# CBASS0_ISC register map
Vendor: Texas Instruments
Registers are 32-bit, read-write, reset 0x0 unless marked. A register's access mark holds for its fields unless they carry their own. Offsets are as the file gives them; [hi:lo] are bit positions; {n}, {i} and the like mark numbered series; 'fields as' and 'values as' point back to an identical list.

## CBASS0_ISC (part 2 of 2)
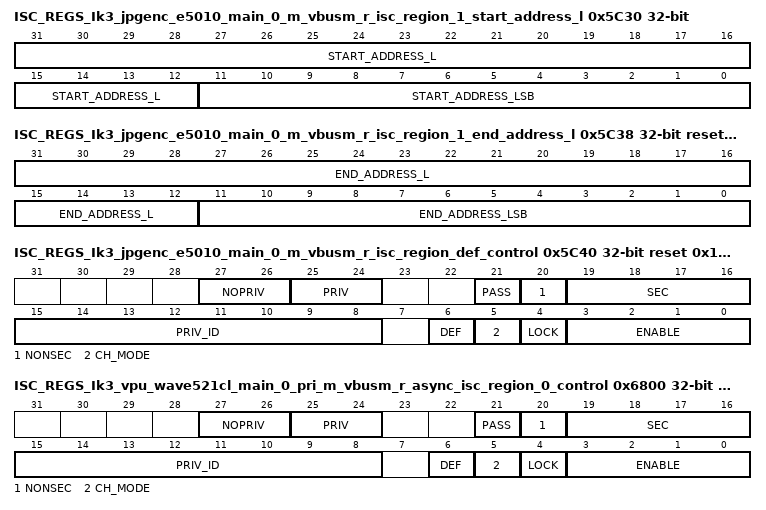
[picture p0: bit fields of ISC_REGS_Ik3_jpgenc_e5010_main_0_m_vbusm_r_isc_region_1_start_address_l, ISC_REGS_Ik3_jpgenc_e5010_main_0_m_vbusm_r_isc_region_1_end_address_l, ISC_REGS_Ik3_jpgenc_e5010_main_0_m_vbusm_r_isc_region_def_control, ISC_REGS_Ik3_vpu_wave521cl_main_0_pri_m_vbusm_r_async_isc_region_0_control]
0x5C30 ISC_REGS_Ik3_jpgenc_e5010_main_0_m_vbusm_r_isc_region_1_start_address_l — The ISC Region 1 Start Address Low Register defines the start address bits 31 to 0 for the initiator Ik3_jpgenc_e5010_main_0.m_vbusm_r region 1 ISC.
  [31:12] START_ADDRESS_L — Start address bits 31 to 12.
  [11:0] START_ADDRESS_LSB — Start address bits 11 to 0 must be 0 as address must be 4KB aligned in address mode. Can also be channel number in channel mode.
0x5C34 ISC_REGS_Ik3_jpgenc_e5010_main_0_m_vbusm_r_isc_region_1_start_address_h — The ISC Region 1 Start Address High Register defines the start address bits 47 to 32 for the initiator Ik3_jpgenc_e5010_main_0.m_vbusm_r region 1 ISC.
  [15:0] START_ADDRESS_H — Start address bits 47 to 32.
0x5C38 ISC_REGS_Ik3_jpgenc_e5010_main_0_m_vbusm_r_isc_region_1_end_address_l access per field reset 0xFFF — The ISC Region 1 End Address Low Register defines the end included address bits 31 to 0 for the initiator Ik3_jpgenc_e5010_main_0.m_vbusm_r region 1 ISC.
  [31:12] END_ADDRESS_L rw — End address bits 31 to 12 to include in the match.
  [11:0] END_ADDRESS_LSB ro — End address bits 11 to 0 are forced to Fs as address must be 4KB aligned.
0x5C3C ISC_REGS_Ik3_jpgenc_e5010_main_0_m_vbusm_r_isc_region_1_end_address_h — The ISC Region 1 End Address High Register defines the end address bits 47 to 32 for the initiator Ik3_jpgenc_e5010_main_0.m_vbusm_r region 1 ISC.
  [15:0] END_ADDRESS_H — End address bits 47 to 32.
0x5C40 ISC_REGS_Ik3_jpgenc_e5010_main_0_m_vbusm_r_isc_region_def_control access not given reset 0x10BE4A — The ISC Default Region Control Register defines the control fields for the initiator Ik3_jpgenc_e5010_main_0.m_vbusm_r region 2 ISC.
  [27:26] NOPRIV rw — Clear output priv attribute. If each bit is set then the outgoing priv bit is cleared, else the bit is unchanged. Do not set both priv and nopriv for the same bit.
  [25:24] PRIV rw — Set outgoing priv attribute. If each bit is set then the outgoing priv bit is set, else the bit is unchanged. Do not set both priv and nopriv for the same bit.
  [21] PASS rw — No privID replacement. A value of 1 will pass through privid value. A value of 0 will replace privid with priv_id field value.
  [20] NONSEC rw — Make outgoing non-secure. A value of 1 forces secure clear, others do nothing. Do not set both sec and nonsec.
  [19:16] SEC rw — Make outgoing secure. A value of 0xA forces secure set, others do nothing. Do not set both sec and nonsec.
  [15:8] PRIV_ID rw — Priv ID value to use if pass is 0.
  [6] DEF ro — Default region indication. The default region is used when all other regions do not match.
  [5] CH_MODE ro — Enable channel mode to match region to a chanid value. Otherwise use address mode to match region to an address range.
  [4] LOCK — Lock region. Once set, the region values cannot be modified. (access R/W1TS)
  [3:0] ENABLE ro — Enable region. A value of 0xA enables, others disable.
{0x6800+0x20*i} ISC_REGS_Ik3_vpu_wave521cl_main_0_pri_m_vbusm_r_async_isc_region_{i}_control access not given reset 0x10BF00 (i=0..4) — The ISC Region {i} Control Register defines the control fields for the initiator Ik3_vpu_wave521cl_main_0.pri_m_vbusm_r_async region {i} ISC.
  [27:26] NOPRIV rw — Clear output priv attribute. If each bit is set then the outgoing priv bit is cleared.
  [25:24] PRIV rw — Set outgoing priv attribute. If each bit is set then the outgoing priv bit is set.
  [21] PASS rw — No privID replacement, pass through value.
  [20] NONSEC rw — Make outgoing non-secure.
  [19:16] SEC rw — Make outgoing secure. A value of 0xA enables, others disable.
  [15:8] PRIV_ID rw
  [6] DEF ro — Default region indication. The default region is used when all other regions do not match.
  [5] CH_MODE rw — Enable channel mode to match region to a chanid value. Otherwise use address mode to match region to an address range.
  [4] LOCK — Lock region. Once set the region values cannot be modified. (access R/W1TS)
  [3:0] ENABLE rw — Enable region. A value of 0xA enables, others disable.
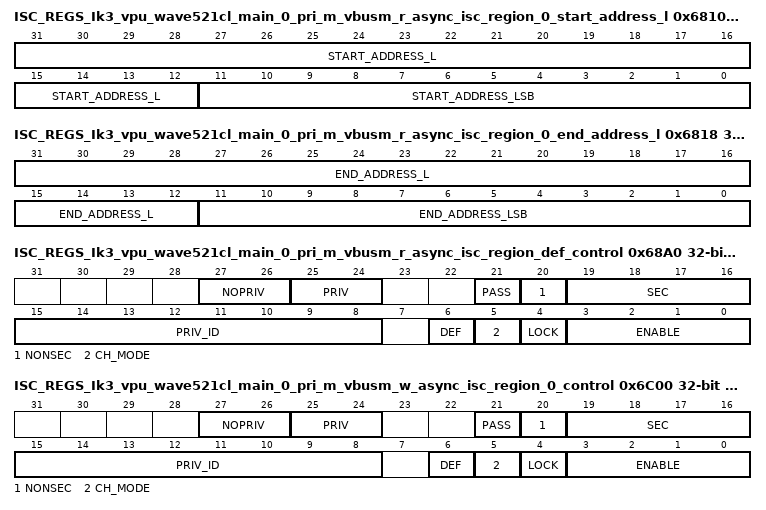
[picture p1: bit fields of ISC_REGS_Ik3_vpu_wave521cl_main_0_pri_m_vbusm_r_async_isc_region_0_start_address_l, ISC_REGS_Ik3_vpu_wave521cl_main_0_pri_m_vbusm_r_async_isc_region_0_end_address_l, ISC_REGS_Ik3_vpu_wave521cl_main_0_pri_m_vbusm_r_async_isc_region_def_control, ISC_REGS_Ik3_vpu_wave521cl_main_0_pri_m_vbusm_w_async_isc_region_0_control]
{0x6810+0x20*i} ISC_REGS_Ik3_vpu_wave521cl_main_0_pri_m_vbusm_r_async_isc_region_{i}_start_address_l (i=0..4) — The ISC Region {i} Start Address Low Register defines the start address bits 31 to 0 for the initiator Ik3_vpu_wave521cl_main_0.pri_m_vbusm_r_async region {i} ISC.
  fields as ISC_REGS_Ik3_jpgenc_e5010_main_0_m_vbusm_r_isc_region_1_start_address_l
{0x6814+0x20*i} ISC_REGS_Ik3_vpu_wave521cl_main_0_pri_m_vbusm_r_async_isc_region_{i}_start_address_h (i=0..4) — The ISC Region {i} Start Address High Register defines the start address bits 47 to 32 for the initiator Ik3_vpu_wave521cl_main_0.pri_m_vbusm_r_async region {i} ISC.
  [15:0] START_ADDRESS_H — Start address bits 47 to 32.
{0x6818+0x20*i} ISC_REGS_Ik3_vpu_wave521cl_main_0_pri_m_vbusm_r_async_isc_region_{i}_end_address_l access per field reset 0xFFF (i=0..4) — The ISC Region {i} End Address Low Register defines the end included address bits 31 to 0 for the initiator Ik3_vpu_wave521cl_main_0.pri_m_vbusm_r_async region {i} ISC.
  fields as ISC_REGS_Ik3_jpgenc_e5010_main_0_m_vbusm_r_isc_region_1_end_address_l
{0x681C+0x20*i} ISC_REGS_Ik3_vpu_wave521cl_main_0_pri_m_vbusm_r_async_isc_region_{i}_end_address_h (i=0..4) — The ISC Region {i} End Address High Register defines the end address bits 47 to 32 for the initiator Ik3_vpu_wave521cl_main_0.pri_m_vbusm_r_async region {i} ISC.
  [15:0] END_ADDRESS_H — End address bits 47 to 32.
0x68A0 ISC_REGS_Ik3_vpu_wave521cl_main_0_pri_m_vbusm_r_async_isc_region_def_control access not given reset 0x10BF4A — The ISC Default Region Control Register defines the control fields for the initiator Ik3_vpu_wave521cl_main_0.pri_m_vbusm_r_async region 5 ISC.
  fields as ISC_REGS_Ik3_jpgenc_e5010_main_0_m_vbusm_r_isc_region_def_control
{0x6C00+0x20*i} ISC_REGS_Ik3_vpu_wave521cl_main_0_pri_m_vbusm_w_async_isc_region_{i}_control access not given reset 0x10BF00 (i=0..4) — The ISC Region {i} Control Register defines the control fields for the initiator Ik3_vpu_wave521cl_main_0.pri_m_vbusm_w_async region {i} ISC.
  fields as ISC_REGS_Ik3_vpu_wave521cl_main_0_pri_m_vbusm_r_async_isc_region_0_control
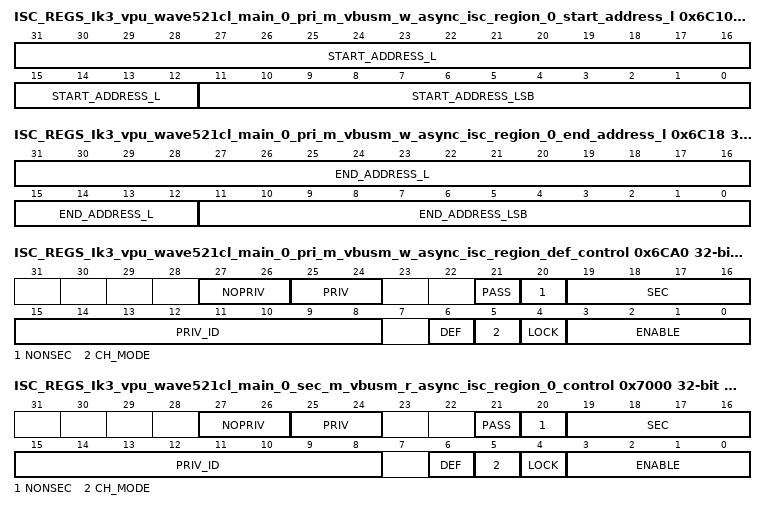
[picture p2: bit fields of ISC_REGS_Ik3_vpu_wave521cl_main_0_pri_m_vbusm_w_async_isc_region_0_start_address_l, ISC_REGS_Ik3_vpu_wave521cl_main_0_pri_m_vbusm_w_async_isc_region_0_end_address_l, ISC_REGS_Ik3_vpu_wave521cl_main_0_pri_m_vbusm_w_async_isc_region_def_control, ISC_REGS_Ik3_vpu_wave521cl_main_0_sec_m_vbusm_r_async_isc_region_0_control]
{0x6C10+0x20*i} ISC_REGS_Ik3_vpu_wave521cl_main_0_pri_m_vbusm_w_async_isc_region_{i}_start_address_l (i=0..4) — The ISC Region {i} Start Address Low Register defines the start address bits 31 to 0 for the initiator Ik3_vpu_wave521cl_main_0.pri_m_vbusm_w_async region {i} ISC.
  fields as ISC_REGS_Ik3_jpgenc_e5010_main_0_m_vbusm_r_isc_region_1_start_address_l
{0x6C14+0x20*i} ISC_REGS_Ik3_vpu_wave521cl_main_0_pri_m_vbusm_w_async_isc_region_{i}_start_address_h (i=0..4) — The ISC Region {i} Start Address High Register defines the start address bits 47 to 32 for the initiator Ik3_vpu_wave521cl_main_0.pri_m_vbusm_w_async region {i} ISC.
  [15:0] START_ADDRESS_H — Start address bits 47 to 32.
{0x6C18+0x20*i} ISC_REGS_Ik3_vpu_wave521cl_main_0_pri_m_vbusm_w_async_isc_region_{i}_end_address_l access per field reset 0xFFF (i=0..4) — The ISC Region {i} End Address Low Register defines the end included address bits 31 to 0 for the initiator Ik3_vpu_wave521cl_main_0.pri_m_vbusm_w_async region {i} ISC.
  fields as ISC_REGS_Ik3_jpgenc_e5010_main_0_m_vbusm_r_isc_region_1_end_address_l
{0x6C1C+0x20*i} ISC_REGS_Ik3_vpu_wave521cl_main_0_pri_m_vbusm_w_async_isc_region_{i}_end_address_h (i=0..4) — The ISC Region {i} End Address High Register defines the end address bits 47 to 32 for the initiator Ik3_vpu_wave521cl_main_0.pri_m_vbusm_w_async region {i} ISC.
  [15:0] END_ADDRESS_H — End address bits 47 to 32.
0x6CA0 ISC_REGS_Ik3_vpu_wave521cl_main_0_pri_m_vbusm_w_async_isc_region_def_control access not given reset 0x10BF4A — The ISC Default Region Control Register defines the control fields for the initiator Ik3_vpu_wave521cl_main_0.pri_m_vbusm_w_async region 5 ISC.
  fields as ISC_REGS_Ik3_jpgenc_e5010_main_0_m_vbusm_r_isc_region_def_control
0x7000 ISC_REGS_Ik3_vpu_wave521cl_main_0_sec_m_vbusm_r_async_isc_region_0_control access not given reset 0x10BF00 — The ISC Region 0 Control Register defines the control fields for the initiator Ik3_vpu_wave521cl_main_0.sec_m_vbusm_r_async region 0 ISC.
  fields as ISC_REGS_Ik3_vpu_wave521cl_main_0_pri_m_vbusm_r_async_isc_region_0_control
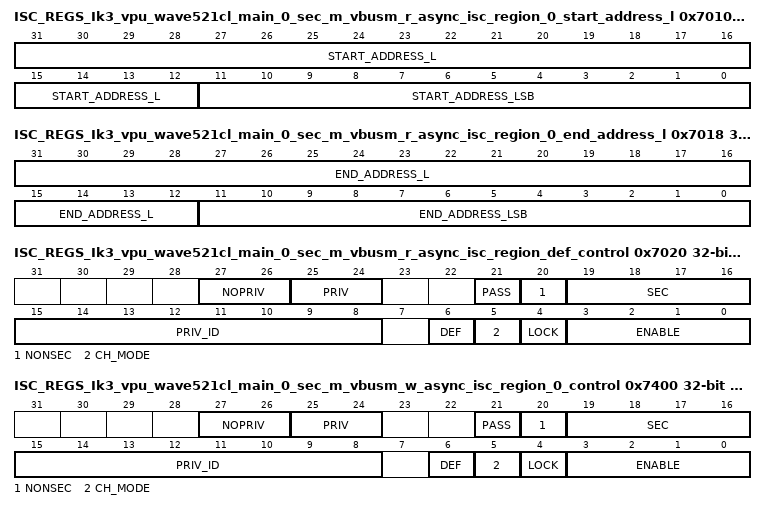
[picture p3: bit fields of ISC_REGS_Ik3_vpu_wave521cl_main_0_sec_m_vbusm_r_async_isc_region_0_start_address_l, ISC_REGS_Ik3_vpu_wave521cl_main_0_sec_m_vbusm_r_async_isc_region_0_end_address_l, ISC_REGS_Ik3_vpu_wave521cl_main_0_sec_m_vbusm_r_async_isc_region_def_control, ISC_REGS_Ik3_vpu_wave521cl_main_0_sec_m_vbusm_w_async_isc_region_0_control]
0x7010 ISC_REGS_Ik3_vpu_wave521cl_main_0_sec_m_vbusm_r_async_isc_region_0_start_address_l — The ISC Region 0 Start Address Low Register defines the start address bits 31 to 0 for the initiator Ik3_vpu_wave521cl_main_0.sec_m_vbusm_r_async region 0 ISC.
  fields as ISC_REGS_Ik3_jpgenc_e5010_main_0_m_vbusm_r_isc_region_1_start_address_l
0x7014 ISC_REGS_Ik3_vpu_wave521cl_main_0_sec_m_vbusm_r_async_isc_region_0_start_address_h — The ISC Region 0 Start Address High Register defines the start address bits 47 to 32 for the initiator Ik3_vpu_wave521cl_main_0.sec_m_vbusm_r_async region 0 ISC.
  [15:0] START_ADDRESS_H — Start address bits 47 to 32.
0x7018 ISC_REGS_Ik3_vpu_wave521cl_main_0_sec_m_vbusm_r_async_isc_region_0_end_address_l access per field reset 0xFFF — The ISC Region 0 End Address Low Register defines the end included address bits 31 to 0 for the initiator Ik3_vpu_wave521cl_main_0.sec_m_vbusm_r_async region 0 ISC.
  fields as ISC_REGS_Ik3_jpgenc_e5010_main_0_m_vbusm_r_isc_region_1_end_address_l
0x701C ISC_REGS_Ik3_vpu_wave521cl_main_0_sec_m_vbusm_r_async_isc_region_0_end_address_h — The ISC Region 0 End Address High Register defines the end address bits 47 to 32 for the initiator Ik3_vpu_wave521cl_main_0.sec_m_vbusm_r_async region 0 ISC.
  [15:0] END_ADDRESS_H — End address bits 47 to 32.
0x7020 ISC_REGS_Ik3_vpu_wave521cl_main_0_sec_m_vbusm_r_async_isc_region_def_control access not given reset 0x10BF4A — The ISC Default Region Control Register defines the control fields for the initiator Ik3_vpu_wave521cl_main_0.sec_m_vbusm_r_async region 1 ISC.
  fields as ISC_REGS_Ik3_jpgenc_e5010_main_0_m_vbusm_r_isc_region_def_control
0x7400 ISC_REGS_Ik3_vpu_wave521cl_main_0_sec_m_vbusm_w_async_isc_region_0_control access not given reset 0x10BF00 — The ISC Region 0 Control Register defines the control fields for the initiator Ik3_vpu_wave521cl_main_0.sec_m_vbusm_w_async region 0 ISC.
  fields as ISC_REGS_Ik3_vpu_wave521cl_main_0_pri_m_vbusm_r_async_isc_region_0_control
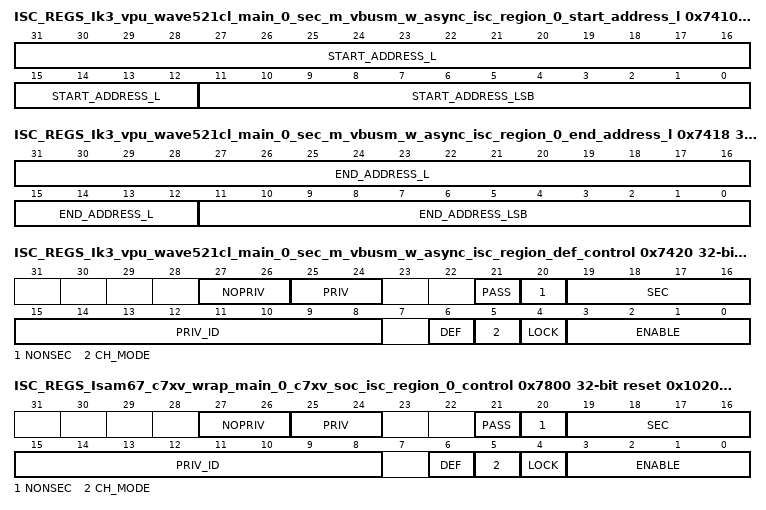
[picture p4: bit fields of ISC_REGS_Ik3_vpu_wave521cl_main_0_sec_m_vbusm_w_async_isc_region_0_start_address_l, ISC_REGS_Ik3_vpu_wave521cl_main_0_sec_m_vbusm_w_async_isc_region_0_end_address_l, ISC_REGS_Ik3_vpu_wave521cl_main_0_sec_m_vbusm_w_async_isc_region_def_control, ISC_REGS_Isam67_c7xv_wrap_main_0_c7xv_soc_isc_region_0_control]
0x7410 ISC_REGS_Ik3_vpu_wave521cl_main_0_sec_m_vbusm_w_async_isc_region_0_start_address_l — The ISC Region 0 Start Address Low Register defines the start address bits 31 to 0 for the initiator Ik3_vpu_wave521cl_main_0.sec_m_vbusm_w_async region 0 ISC.
  fields as ISC_REGS_Ik3_jpgenc_e5010_main_0_m_vbusm_r_isc_region_1_start_address_l
0x7414 ISC_REGS_Ik3_vpu_wave521cl_main_0_sec_m_vbusm_w_async_isc_region_0_start_address_h — The ISC Region 0 Start Address High Register defines the start address bits 47 to 32 for the initiator Ik3_vpu_wave521cl_main_0.sec_m_vbusm_w_async region 0 ISC.
  [15:0] START_ADDRESS_H — Start address bits 47 to 32.
0x7418 ISC_REGS_Ik3_vpu_wave521cl_main_0_sec_m_vbusm_w_async_isc_region_0_end_address_l access per field reset 0xFFF — The ISC Region 0 End Address Low Register defines the end included address bits 31 to 0 for the initiator Ik3_vpu_wave521cl_main_0.sec_m_vbusm_w_async region 0 ISC.
  fields as ISC_REGS_Ik3_jpgenc_e5010_main_0_m_vbusm_r_isc_region_1_end_address_l
0x741C ISC_REGS_Ik3_vpu_wave521cl_main_0_sec_m_vbusm_w_async_isc_region_0_end_address_h — The ISC Region 0 End Address High Register defines the end address bits 47 to 32 for the initiator Ik3_vpu_wave521cl_main_0.sec_m_vbusm_w_async region 0 ISC.
  [15:0] END_ADDRESS_H — End address bits 47 to 32.
0x7420 ISC_REGS_Ik3_vpu_wave521cl_main_0_sec_m_vbusm_w_async_isc_region_def_control access not given reset 0x10BF4A — The ISC Default Region Control Register defines the control fields for the initiator Ik3_vpu_wave521cl_main_0.sec_m_vbusm_w_async region 1 ISC.
  fields as ISC_REGS_Ik3_jpgenc_e5010_main_0_m_vbusm_r_isc_region_def_control
0x7800 ISC_REGS_Isam67_c7xv_wrap_main_0_c7xv_soc_isc_region_0_control access not given reset 0x102000 — The ISC Region 0 Control Register defines the control fields for the initiator Isam67_c7xv_wrap_main_0.c7xv_soc region 0 ISC.
  fields as ISC_REGS_Ik3_vpu_wave521cl_main_0_pri_m_vbusm_r_async_isc_region_0_control
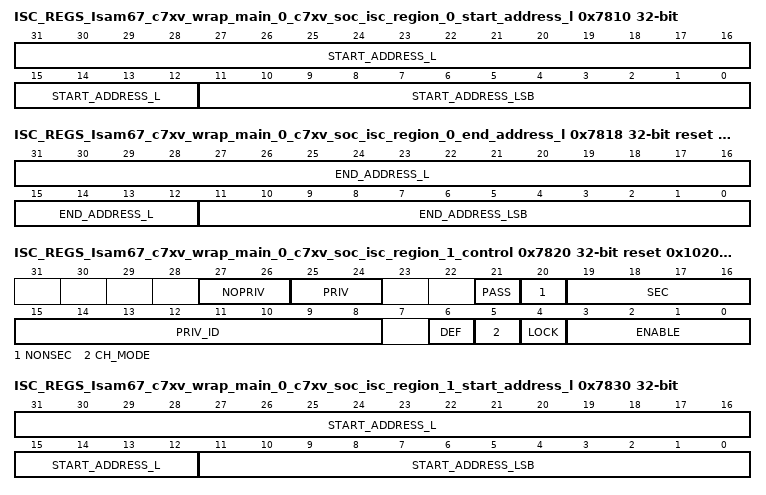
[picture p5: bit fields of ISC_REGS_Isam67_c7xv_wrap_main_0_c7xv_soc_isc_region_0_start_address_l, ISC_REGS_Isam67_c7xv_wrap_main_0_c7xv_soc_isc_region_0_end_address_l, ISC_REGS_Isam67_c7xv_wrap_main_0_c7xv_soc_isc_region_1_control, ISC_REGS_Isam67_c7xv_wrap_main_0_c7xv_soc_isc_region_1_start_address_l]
0x7810 ISC_REGS_Isam67_c7xv_wrap_main_0_c7xv_soc_isc_region_0_start_address_l — The ISC Region 0 Start Address Low Register defines the start address bits 31 to 0 for the initiator Isam67_c7xv_wrap_main_0.c7xv_soc region 0 ISC.
  fields as ISC_REGS_Ik3_jpgenc_e5010_main_0_m_vbusm_r_isc_region_1_start_address_l
0x7814 ISC_REGS_Isam67_c7xv_wrap_main_0_c7xv_soc_isc_region_0_start_address_h — The ISC Region 0 Start Address High Register defines the start address bits 47 to 32 for the initiator Isam67_c7xv_wrap_main_0.c7xv_soc region 0 ISC.
  [15:0] START_ADDRESS_H — Start address bits 47 to 32.
0x7818 ISC_REGS_Isam67_c7xv_wrap_main_0_c7xv_soc_isc_region_0_end_address_l access per field reset 0xFFF — The ISC Region 0 End Address Low Register defines the end included address bits 31 to 0 for the initiator Isam67_c7xv_wrap_main_0.c7xv_soc region 0 ISC.
  fields as ISC_REGS_Ik3_jpgenc_e5010_main_0_m_vbusm_r_isc_region_1_end_address_l
0x781C ISC_REGS_Isam67_c7xv_wrap_main_0_c7xv_soc_isc_region_0_end_address_h — The ISC Region 0 End Address High Register defines the end address bits 47 to 32 for the initiator Isam67_c7xv_wrap_main_0.c7xv_soc region 0 ISC.
  [15:0] END_ADDRESS_H — End address bits 47 to 32.
0x7820 ISC_REGS_Isam67_c7xv_wrap_main_0_c7xv_soc_isc_region_1_control access not given reset 0x102000 — The ISC Region 1 Control Register defines the control fields for the initiator Isam67_c7xv_wrap_main_0.c7xv_soc region 1 ISC.
  fields as ISC_REGS_Ik3_vpu_wave521cl_main_0_pri_m_vbusm_r_async_isc_region_0_control
0x7830 ISC_REGS_Isam67_c7xv_wrap_main_0_c7xv_soc_isc_region_1_start_address_l — The ISC Region 1 Start Address Low Register defines the start address bits 31 to 0 for the initiator Isam67_c7xv_wrap_main_0.c7xv_soc region 1 ISC.
  fields as ISC_REGS_Ik3_jpgenc_e5010_main_0_m_vbusm_r_isc_region_1_start_address_l
0x7834 ISC_REGS_Isam67_c7xv_wrap_main_0_c7xv_soc_isc_region_1_start_address_h — The ISC Region 1 Start Address High Register defines the start address bits 47 to 32 for the initiator Isam67_c7xv_wrap_main_0.c7xv_soc region 1 ISC.
  [15:0] START_ADDRESS_H — Start address bits 47 to 32.
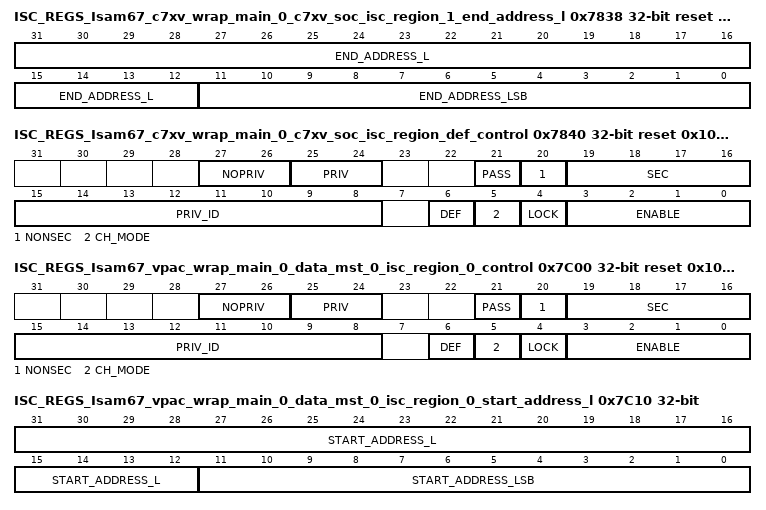
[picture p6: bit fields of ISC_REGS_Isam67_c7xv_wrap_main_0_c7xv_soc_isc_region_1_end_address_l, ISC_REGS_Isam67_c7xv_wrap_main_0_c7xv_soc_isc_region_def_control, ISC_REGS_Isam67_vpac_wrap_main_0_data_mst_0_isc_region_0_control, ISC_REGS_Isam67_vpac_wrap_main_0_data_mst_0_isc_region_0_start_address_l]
0x7838 ISC_REGS_Isam67_c7xv_wrap_main_0_c7xv_soc_isc_region_1_end_address_l access per field reset 0xFFF — The ISC Region 1 End Address Low Register defines the end included address bits 31 to 0 for the initiator Isam67_c7xv_wrap_main_0.c7xv_soc region 1 ISC.
  fields as ISC_REGS_Ik3_jpgenc_e5010_main_0_m_vbusm_r_isc_region_1_end_address_l
0x783C ISC_REGS_Isam67_c7xv_wrap_main_0_c7xv_soc_isc_region_1_end_address_h — The ISC Region 1 End Address High Register defines the end address bits 47 to 32 for the initiator Isam67_c7xv_wrap_main_0.c7xv_soc region 1 ISC.
  [15:0] END_ADDRESS_H — End address bits 47 to 32.
0x7840 ISC_REGS_Isam67_c7xv_wrap_main_0_c7xv_soc_isc_region_def_control access not given reset 0x10204A — The ISC Default Region Control Register defines the control fields for the initiator Isam67_c7xv_wrap_main_0.c7xv_soc region 2 ISC.
  fields as ISC_REGS_Ik3_jpgenc_e5010_main_0_m_vbusm_r_isc_region_def_control
0x7C00 ISC_REGS_Isam67_vpac_wrap_main_0_data_mst_0_isc_region_0_control access not given reset 0x106600 — The ISC Region 0 Control Register defines the control fields for the initiator Isam67_vpac_wrap_main_0.data_mst_0 region 0 ISC.
  fields as ISC_REGS_Ik3_vpu_wave521cl_main_0_pri_m_vbusm_r_async_isc_region_0_control
0x7C10 ISC_REGS_Isam67_vpac_wrap_main_0_data_mst_0_isc_region_0_start_address_l — The ISC Region 0 Start Address Low Register defines the start address bits 31 to 0 for the initiator Isam67_vpac_wrap_main_0.data_mst_0 region 0 ISC.
  fields as ISC_REGS_Ik3_jpgenc_e5010_main_0_m_vbusm_r_isc_region_1_start_address_l
0x7C14 ISC_REGS_Isam67_vpac_wrap_main_0_data_mst_0_isc_region_0_start_address_h — The ISC Region 0 Start Address High Register defines the start address bits 47 to 32 for the initiator Isam67_vpac_wrap_main_0.data_mst_0 region 0 ISC.
  [15:0] START_ADDRESS_H — Start address bits 47 to 32.
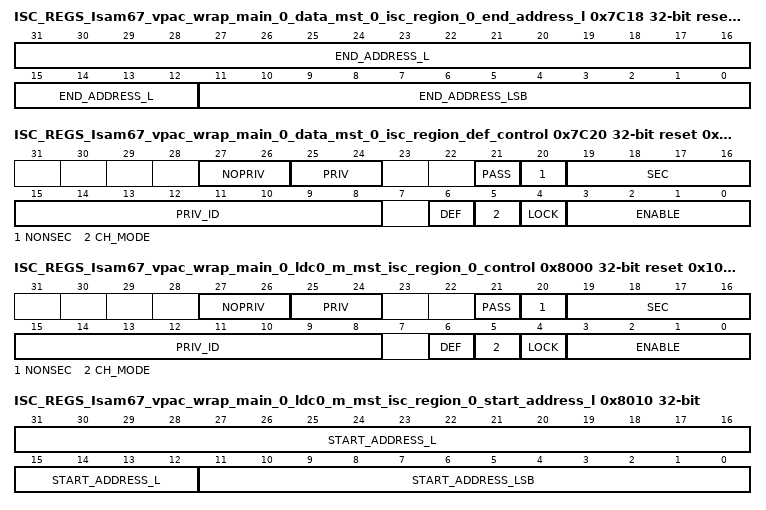
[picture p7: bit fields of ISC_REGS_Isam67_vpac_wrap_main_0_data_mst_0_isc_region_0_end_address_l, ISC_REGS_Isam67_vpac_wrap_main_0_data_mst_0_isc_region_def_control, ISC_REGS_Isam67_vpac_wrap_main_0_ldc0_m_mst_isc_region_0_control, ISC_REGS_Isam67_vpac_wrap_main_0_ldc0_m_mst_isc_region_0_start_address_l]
0x7C18 ISC_REGS_Isam67_vpac_wrap_main_0_data_mst_0_isc_region_0_end_address_l access per field reset 0xFFF — The ISC Region 0 End Address Low Register defines the end included address bits 31 to 0 for the initiator Isam67_vpac_wrap_main_0.data_mst_0 region 0 ISC.
  fields as ISC_REGS_Ik3_jpgenc_e5010_main_0_m_vbusm_r_isc_region_1_end_address_l
0x7C1C ISC_REGS_Isam67_vpac_wrap_main_0_data_mst_0_isc_region_0_end_address_h — The ISC Region 0 End Address High Register defines the end address bits 47 to 32 for the initiator Isam67_vpac_wrap_main_0.data_mst_0 region 0 ISC.
  [15:0] END_ADDRESS_H — End address bits 47 to 32.
0x7C20 ISC_REGS_Isam67_vpac_wrap_main_0_data_mst_0_isc_region_def_control access not given reset 0x10664A — The ISC Default Region Control Register defines the control fields for the initiator Isam67_vpac_wrap_main_0.data_mst_0 region 1 ISC.
  fields as ISC_REGS_Ik3_jpgenc_e5010_main_0_m_vbusm_r_isc_region_def_control
0x8000 ISC_REGS_Isam67_vpac_wrap_main_0_ldc0_m_mst_isc_region_0_control access not given reset 0x106800 — The ISC Region 0 Control Register defines the control fields for the initiator Isam67_vpac_wrap_main_0.ldc0_m_mst region 0 ISC.
  fields as ISC_REGS_Ik3_vpu_wave521cl_main_0_pri_m_vbusm_r_async_isc_region_0_control
0x8010 ISC_REGS_Isam67_vpac_wrap_main_0_ldc0_m_mst_isc_region_0_start_address_l — The ISC Region 0 Start Address Low Register defines the start address bits 31 to 0 for the initiator Isam67_vpac_wrap_main_0.ldc0_m_mst region 0 ISC.
  fields as ISC_REGS_Ik3_jpgenc_e5010_main_0_m_vbusm_r_isc_region_1_start_address_l
0x8014 ISC_REGS_Isam67_vpac_wrap_main_0_ldc0_m_mst_isc_region_0_start_address_h — The ISC Region 0 Start Address High Register defines the start address bits 47 to 32 for the initiator Isam67_vpac_wrap_main_0.ldc0_m_mst region 0 ISC.
  [15:0] START_ADDRESS_H — Start address bits 47 to 32.
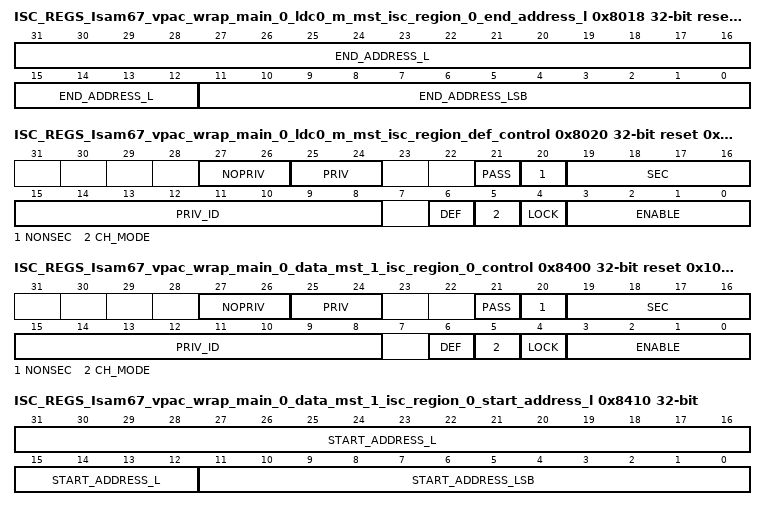
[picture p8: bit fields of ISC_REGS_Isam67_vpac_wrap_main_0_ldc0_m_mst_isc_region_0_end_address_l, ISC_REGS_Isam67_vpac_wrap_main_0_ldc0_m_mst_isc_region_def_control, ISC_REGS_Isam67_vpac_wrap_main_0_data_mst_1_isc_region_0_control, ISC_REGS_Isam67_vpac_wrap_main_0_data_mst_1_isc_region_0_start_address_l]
0x8018 ISC_REGS_Isam67_vpac_wrap_main_0_ldc0_m_mst_isc_region_0_end_address_l access per field reset 0xFFF — The ISC Region 0 End Address Low Register defines the end included address bits 31 to 0 for the initiator Isam67_vpac_wrap_main_0.ldc0_m_mst region 0 ISC.
  fields as ISC_REGS_Ik3_jpgenc_e5010_main_0_m_vbusm_r_isc_region_1_end_address_l
0x801C ISC_REGS_Isam67_vpac_wrap_main_0_ldc0_m_mst_isc_region_0_end_address_h — The ISC Region 0 End Address High Register defines the end address bits 47 to 32 for the initiator Isam67_vpac_wrap_main_0.ldc0_m_mst region 0 ISC.
  [15:0] END_ADDRESS_H — End address bits 47 to 32.
0x8020 ISC_REGS_Isam67_vpac_wrap_main_0_ldc0_m_mst_isc_region_def_control access not given reset 0x10684A — The ISC Default Region Control Register defines the control fields for the initiator Isam67_vpac_wrap_main_0.ldc0_m_mst region 1 ISC.
  fields as ISC_REGS_Ik3_jpgenc_e5010_main_0_m_vbusm_r_isc_region_def_control
0x8400 ISC_REGS_Isam67_vpac_wrap_main_0_data_mst_1_isc_region_0_control access not given reset 0x106700 — The ISC Region 0 Control Register defines the control fields for the initiator Isam67_vpac_wrap_main_0.data_mst_1 region 0 ISC.
  fields as ISC_REGS_Ik3_vpu_wave521cl_main_0_pri_m_vbusm_r_async_isc_region_0_control
0x8410 ISC_REGS_Isam67_vpac_wrap_main_0_data_mst_1_isc_region_0_start_address_l — The ISC Region 0 Start Address Low Register defines the start address bits 31 to 0 for the initiator Isam67_vpac_wrap_main_0.data_mst_1 region 0 ISC.
  fields as ISC_REGS_Ik3_jpgenc_e5010_main_0_m_vbusm_r_isc_region_1_start_address_l
0x8414 ISC_REGS_Isam67_vpac_wrap_main_0_data_mst_1_isc_region_0_start_address_h — The ISC Region 0 Start Address High Register defines the start address bits 47 to 32 for the initiator Isam67_vpac_wrap_main_0.data_mst_1 region 0 ISC.
  [15:0] START_ADDRESS_H — Start address bits 47 to 32.
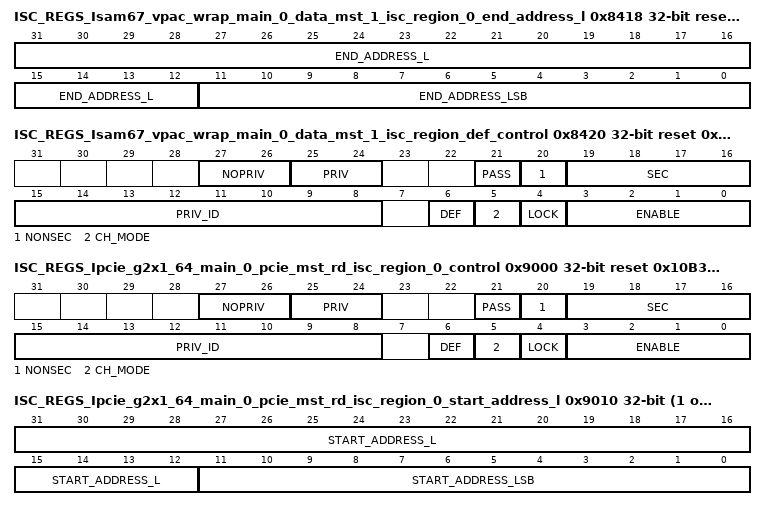
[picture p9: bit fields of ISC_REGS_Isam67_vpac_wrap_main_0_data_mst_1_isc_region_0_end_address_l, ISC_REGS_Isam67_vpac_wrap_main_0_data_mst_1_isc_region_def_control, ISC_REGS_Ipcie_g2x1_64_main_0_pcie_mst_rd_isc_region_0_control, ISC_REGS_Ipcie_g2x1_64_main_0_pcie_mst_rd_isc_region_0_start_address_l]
0x8418 ISC_REGS_Isam67_vpac_wrap_main_0_data_mst_1_isc_region_0_end_address_l access per field reset 0xFFF — The ISC Region 0 End Address Low Register defines the end included address bits 31 to 0 for the initiator Isam67_vpac_wrap_main_0.data_mst_1 region 0 ISC.
  fields as ISC_REGS_Ik3_jpgenc_e5010_main_0_m_vbusm_r_isc_region_1_end_address_l
0x841C ISC_REGS_Isam67_vpac_wrap_main_0_data_mst_1_isc_region_0_end_address_h — The ISC Region 0 End Address High Register defines the end address bits 47 to 32 for the initiator Isam67_vpac_wrap_main_0.data_mst_1 region 0 ISC.
  [15:0] END_ADDRESS_H — End address bits 47 to 32.
0x8420 ISC_REGS_Isam67_vpac_wrap_main_0_data_mst_1_isc_region_def_control access not given reset 0x10674A — The ISC Default Region Control Register defines the control fields for the initiator Isam67_vpac_wrap_main_0.data_mst_1 region 1 ISC.
  fields as ISC_REGS_Ik3_jpgenc_e5010_main_0_m_vbusm_r_isc_region_def_control
{0x9000+0x20*i} ISC_REGS_Ipcie_g2x1_64_main_0_pcie_mst_rd_isc_region_{i}_control access not given reset 0x10B300 (i=0..7) — The ISC Region {i} Control Register defines the control fields for the initiator Ipcie_g2x1_64_main_0.pcie_mst_rd region {i} ISC.
  fields as ISC_REGS_Ik3_vpu_wave521cl_main_0_pri_m_vbusm_r_async_isc_region_0_control
{0x9010+0x20*i} ISC_REGS_Ipcie_g2x1_64_main_0_pcie_mst_rd_isc_region_{i}_start_address_l (i=0..7) — The ISC Region {i} Start Address Low Register defines the start address bits 31 to 0 for the initiator Ipcie_g2x1_64_main_0.pcie_mst_rd region {i} ISC.
  fields as ISC_REGS_Ik3_jpgenc_e5010_main_0_m_vbusm_r_isc_region_1_start_address_l
{0x9014+0x20*i} ISC_REGS_Ipcie_g2x1_64_main_0_pcie_mst_rd_isc_region_{i}_start_address_h (i=0..7) — The ISC Region {i} Start Address High Register defines the start address bits 47 to 32 for the initiator Ipcie_g2x1_64_main_0.pcie_mst_rd region {i} ISC.
  [15:0] START_ADDRESS_H — Start address bits 47 to 32.
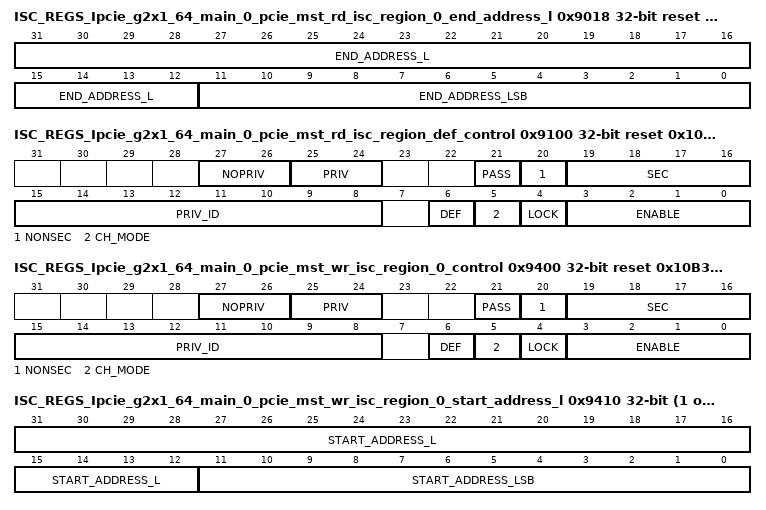
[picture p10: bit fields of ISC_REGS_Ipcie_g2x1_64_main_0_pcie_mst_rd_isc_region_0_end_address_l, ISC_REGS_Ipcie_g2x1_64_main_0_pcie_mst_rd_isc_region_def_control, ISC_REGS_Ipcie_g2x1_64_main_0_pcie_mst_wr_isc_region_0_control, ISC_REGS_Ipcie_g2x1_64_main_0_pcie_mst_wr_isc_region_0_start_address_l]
{0x9018+0x20*i} ISC_REGS_Ipcie_g2x1_64_main_0_pcie_mst_rd_isc_region_{i}_end_address_l access per field reset 0xFFF (i=0..7) — The ISC Region {i} End Address Low Register defines the end included address bits 31 to 0 for the initiator Ipcie_g2x1_64_main_0.pcie_mst_rd region {i} ISC.
  fields as ISC_REGS_Ik3_jpgenc_e5010_main_0_m_vbusm_r_isc_region_1_end_address_l
{0x901C+0x20*i} ISC_REGS_Ipcie_g2x1_64_main_0_pcie_mst_rd_isc_region_{i}_end_address_h (i=0..7) — The ISC Region {i} End Address High Register defines the end address bits 47 to 32 for the initiator Ipcie_g2x1_64_main_0.pcie_mst_rd region {i} ISC.
  [15:0] END_ADDRESS_H — End address bits 47 to 32.
0x9100 ISC_REGS_Ipcie_g2x1_64_main_0_pcie_mst_rd_isc_region_def_control access not given reset 0x10B34A — The ISC Default Region Control Register defines the control fields for the initiator Ipcie_g2x1_64_main_0.pcie_mst_rd region 8 ISC.
  fields as ISC_REGS_Ik3_jpgenc_e5010_main_0_m_vbusm_r_isc_region_def_control
{0x9400+0x20*i} ISC_REGS_Ipcie_g2x1_64_main_0_pcie_mst_wr_isc_region_{i}_control access not given reset 0x10B300 (i=0..7) — The ISC Region {i} Control Register defines the control fields for the initiator Ipcie_g2x1_64_main_0.pcie_mst_wr region {i} ISC.
  fields as ISC_REGS_Ik3_vpu_wave521cl_main_0_pri_m_vbusm_r_async_isc_region_0_control
{0x9410+0x20*i} ISC_REGS_Ipcie_g2x1_64_main_0_pcie_mst_wr_isc_region_{i}_start_address_l (i=0..7) — The ISC Region {i} Start Address Low Register defines the start address bits 31 to 0 for the initiator Ipcie_g2x1_64_main_0.pcie_mst_wr region {i} ISC.
  fields as ISC_REGS_Ik3_jpgenc_e5010_main_0_m_vbusm_r_isc_region_1_start_address_l
{0x9414+0x20*i} ISC_REGS_Ipcie_g2x1_64_main_0_pcie_mst_wr_isc_region_{i}_start_address_h (i=0..7) — The ISC Region {i} Start Address High Register defines the start address bits 47 to 32 for the initiator Ipcie_g2x1_64_main_0.pcie_mst_wr region {i} ISC.
  [15:0] START_ADDRESS_H — Start address bits 47 to 32.
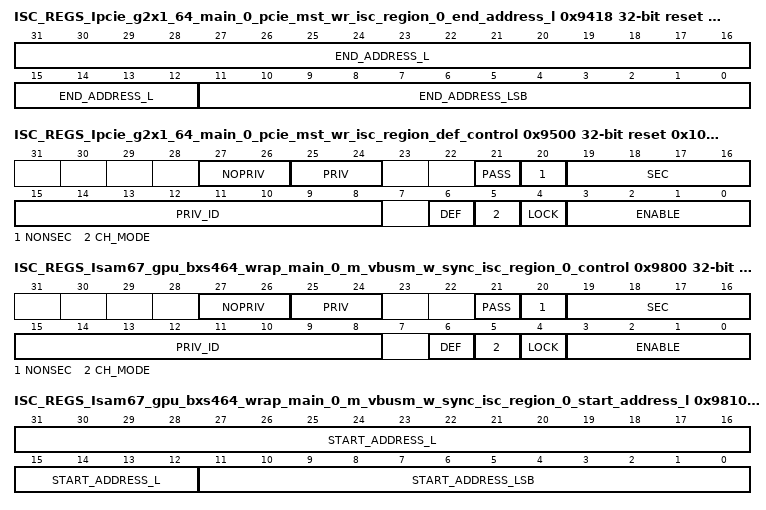
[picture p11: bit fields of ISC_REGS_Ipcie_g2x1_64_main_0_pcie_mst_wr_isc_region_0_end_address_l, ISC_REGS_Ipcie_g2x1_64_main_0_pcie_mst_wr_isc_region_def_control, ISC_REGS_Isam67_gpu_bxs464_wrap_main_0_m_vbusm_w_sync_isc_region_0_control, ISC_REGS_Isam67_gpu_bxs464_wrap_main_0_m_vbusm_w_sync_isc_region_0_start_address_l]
{0x9418+0x20*i} ISC_REGS_Ipcie_g2x1_64_main_0_pcie_mst_wr_isc_region_{i}_end_address_l access per field reset 0xFFF (i=0..7) — The ISC Region {i} End Address Low Register defines the end included address bits 31 to 0 for the initiator Ipcie_g2x1_64_main_0.pcie_mst_wr region {i} ISC.
  fields as ISC_REGS_Ik3_jpgenc_e5010_main_0_m_vbusm_r_isc_region_1_end_address_l
{0x941C+0x20*i} ISC_REGS_Ipcie_g2x1_64_main_0_pcie_mst_wr_isc_region_{i}_end_address_h (i=0..7) — The ISC Region {i} End Address High Register defines the end address bits 47 to 32 for the initiator Ipcie_g2x1_64_main_0.pcie_mst_wr region {i} ISC.
  [15:0] END_ADDRESS_H — End address bits 47 to 32.
0x9500 ISC_REGS_Ipcie_g2x1_64_main_0_pcie_mst_wr_isc_region_def_control access not given reset 0x10B34A — The ISC Default Region Control Register defines the control fields for the initiator Ipcie_g2x1_64_main_0.pcie_mst_wr region 8 ISC.
  fields as ISC_REGS_Ik3_jpgenc_e5010_main_0_m_vbusm_r_isc_region_def_control
{0x9800+0x20*i} ISC_REGS_Isam67_gpu_bxs464_wrap_main_0_m_vbusm_w_sync_isc_region_{i}_control access not given reset 0x10BB00 (i=0..31) — The ISC Region {i} Control Register defines the control fields for the initiator Isam67_gpu_bxs464_wrap_main_0.m_vbusm_w_sync region {i} ISC.
  fields as ISC_REGS_Ik3_vpu_wave521cl_main_0_pri_m_vbusm_r_async_isc_region_0_control
{0x9810+0x20*i} ISC_REGS_Isam67_gpu_bxs464_wrap_main_0_m_vbusm_w_sync_isc_region_{i}_start_address_l (i=0..31) — The ISC Region {i} Start Address Low Register defines the start address bits 31 to 0 for the initiator Isam67_gpu_bxs464_wrap_main_0.m_vbusm_w_sync region {i} ISC.
  fields as ISC_REGS_Ik3_jpgenc_e5010_main_0_m_vbusm_r_isc_region_1_start_address_l
{0x9814+0x20*i} ISC_REGS_Isam67_gpu_bxs464_wrap_main_0_m_vbusm_w_sync_isc_region_{i}_start_address_h (i=0..31) — The ISC Region {i} Start Address High Register defines the start address bits 47 to 32 for the initiator Isam67_gpu_bxs464_wrap_main_0.m_vbusm_w_sync region {i} ISC.
  [15:0] START_ADDRESS_H — Start address bits 47 to 32.
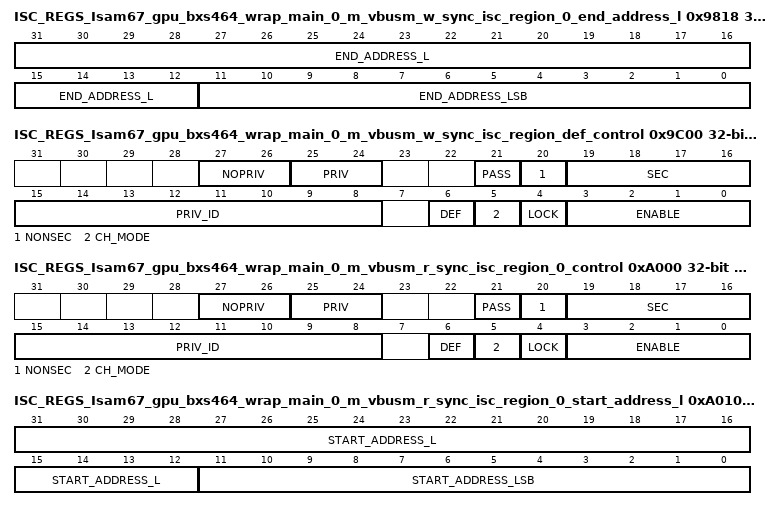
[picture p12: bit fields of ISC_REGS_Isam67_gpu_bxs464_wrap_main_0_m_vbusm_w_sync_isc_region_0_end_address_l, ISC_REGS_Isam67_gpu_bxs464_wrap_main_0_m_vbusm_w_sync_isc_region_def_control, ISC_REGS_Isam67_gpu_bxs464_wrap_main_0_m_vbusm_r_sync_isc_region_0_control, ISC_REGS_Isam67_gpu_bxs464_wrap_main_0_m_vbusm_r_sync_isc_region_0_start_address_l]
{0x9818+0x20*i} ISC_REGS_Isam67_gpu_bxs464_wrap_main_0_m_vbusm_w_sync_isc_region_{i}_end_address_l access per field reset 0xFFF (i=0..31) — The ISC Region {i} End Address Low Register defines the end included address bits 31 to 0 for the initiator Isam67_gpu_bxs464_wrap_main_0.m_vbusm_w_sync region {i} ISC.
  fields as ISC_REGS_Ik3_jpgenc_e5010_main_0_m_vbusm_r_isc_region_1_end_address_l
{0x981C+0x20*i} ISC_REGS_Isam67_gpu_bxs464_wrap_main_0_m_vbusm_w_sync_isc_region_{i}_end_address_h (i=0..31) — The ISC Region {i} End Address High Register defines the end address bits 47 to 32 for the initiator Isam67_gpu_bxs464_wrap_main_0.m_vbusm_w_sync region {i} ISC.
  [15:0] END_ADDRESS_H — End address bits 47 to 32.
0x9C00 ISC_REGS_Isam67_gpu_bxs464_wrap_main_0_m_vbusm_w_sync_isc_region_def_control access not given reset 0x10BB4A — The ISC Default Region Control Register defines the control fields for the initiator Isam67_gpu_bxs464_wrap_main_0.m_vbusm_w_sync region 32 ISC.
  fields as ISC_REGS_Ik3_jpgenc_e5010_main_0_m_vbusm_r_isc_region_def_control
{0xA000+0x20*i} ISC_REGS_Isam67_gpu_bxs464_wrap_main_0_m_vbusm_r_sync_isc_region_{i}_control access not given reset 0x10BB00 (i=0..31) — The ISC Region {i} Control Register defines the control fields for the initiator Isam67_gpu_bxs464_wrap_main_0.m_vbusm_r_sync region {i} ISC.
  fields as ISC_REGS_Ik3_vpu_wave521cl_main_0_pri_m_vbusm_r_async_isc_region_0_control
{0xA010+0x20*i} ISC_REGS_Isam67_gpu_bxs464_wrap_main_0_m_vbusm_r_sync_isc_region_{i}_start_address_l (i=0..31) — The ISC Region {i} Start Address Low Register defines the start address bits 31 to 0 for the initiator Isam67_gpu_bxs464_wrap_main_0.m_vbusm_r_sync region {i} ISC.
  fields as ISC_REGS_Ik3_jpgenc_e5010_main_0_m_vbusm_r_isc_region_1_start_address_l
{0xA014+0x20*i} ISC_REGS_Isam67_gpu_bxs464_wrap_main_0_m_vbusm_r_sync_isc_region_{i}_start_address_h (i=0..31) — The ISC Region {i} Start Address High Register defines the start address bits 47 to 32 for the initiator Isam67_gpu_bxs464_wrap_main_0.m_vbusm_r_sync region {i} ISC.
  [15:0] START_ADDRESS_H — Start address bits 47 to 32.
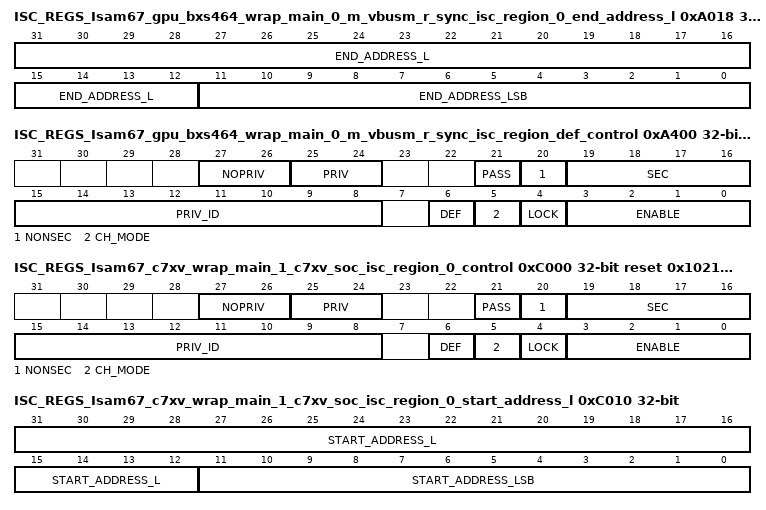
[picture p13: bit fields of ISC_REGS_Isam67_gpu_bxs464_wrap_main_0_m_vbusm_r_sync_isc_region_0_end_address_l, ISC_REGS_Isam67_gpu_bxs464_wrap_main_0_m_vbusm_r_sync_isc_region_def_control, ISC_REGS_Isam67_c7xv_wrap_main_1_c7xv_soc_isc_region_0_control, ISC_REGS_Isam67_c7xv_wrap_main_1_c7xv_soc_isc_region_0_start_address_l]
{0xA018+0x20*i} ISC_REGS_Isam67_gpu_bxs464_wrap_main_0_m_vbusm_r_sync_isc_region_{i}_end_address_l access per field reset 0xFFF (i=0..31) — The ISC Region {i} End Address Low Register defines the end included address bits 31 to 0 for the initiator Isam67_gpu_bxs464_wrap_main_0.m_vbusm_r_sync region {i} ISC.
  fields as ISC_REGS_Ik3_jpgenc_e5010_main_0_m_vbusm_r_isc_region_1_end_address_l
{0xA01C+0x20*i} ISC_REGS_Isam67_gpu_bxs464_wrap_main_0_m_vbusm_r_sync_isc_region_{i}_end_address_h (i=0..31) — The ISC Region {i} End Address High Register defines the end address bits 47 to 32 for the initiator Isam67_gpu_bxs464_wrap_main_0.m_vbusm_r_sync region {i} ISC.
  [15:0] END_ADDRESS_H — End address bits 47 to 32.
0xA400 ISC_REGS_Isam67_gpu_bxs464_wrap_main_0_m_vbusm_r_sync_isc_region_def_control access not given reset 0x10BB4A — The ISC Default Region Control Register defines the control fields for the initiator Isam67_gpu_bxs464_wrap_main_0.m_vbusm_r_sync region 32 ISC.
  fields as ISC_REGS_Ik3_jpgenc_e5010_main_0_m_vbusm_r_isc_region_def_control
0xC000 ISC_REGS_Isam67_c7xv_wrap_main_1_c7xv_soc_isc_region_0_control access not given reset 0x102100 — The ISC Region 0 Control Register defines the control fields for the initiator Isam67_c7xv_wrap_main_1.c7xv_soc region 0 ISC.
  fields as ISC_REGS_Ik3_vpu_wave521cl_main_0_pri_m_vbusm_r_async_isc_region_0_control
0xC010 ISC_REGS_Isam67_c7xv_wrap_main_1_c7xv_soc_isc_region_0_start_address_l — The ISC Region 0 Start Address Low Register defines the start address bits 31 to 0 for the initiator Isam67_c7xv_wrap_main_1.c7xv_soc region 0 ISC.
  fields as ISC_REGS_Ik3_jpgenc_e5010_main_0_m_vbusm_r_isc_region_1_start_address_l
0xC014 ISC_REGS_Isam67_c7xv_wrap_main_1_c7xv_soc_isc_region_0_start_address_h — The ISC Region 0 Start Address High Register defines the start address bits 47 to 32 for the initiator Isam67_c7xv_wrap_main_1.c7xv_soc region 0 ISC.
  [15:0] START_ADDRESS_H — Start address bits 47 to 32.
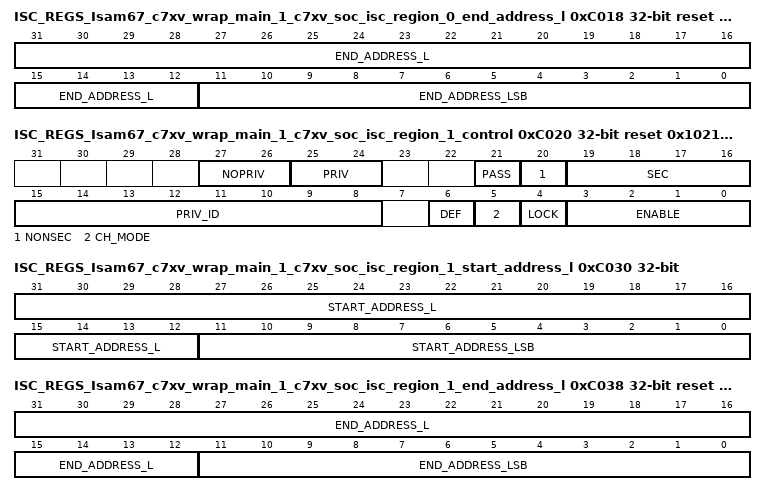
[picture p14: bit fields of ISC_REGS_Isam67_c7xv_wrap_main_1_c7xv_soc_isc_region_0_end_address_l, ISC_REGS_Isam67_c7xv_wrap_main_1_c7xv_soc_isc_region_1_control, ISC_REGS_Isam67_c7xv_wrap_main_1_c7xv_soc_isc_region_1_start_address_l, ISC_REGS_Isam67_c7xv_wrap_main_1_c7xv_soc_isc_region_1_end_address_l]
0xC018 ISC_REGS_Isam67_c7xv_wrap_main_1_c7xv_soc_isc_region_0_end_address_l access per field reset 0xFFF — The ISC Region 0 End Address Low Register defines the end included address bits 31 to 0 for the initiator Isam67_c7xv_wrap_main_1.c7xv_soc region 0 ISC.
  fields as ISC_REGS_Ik3_jpgenc_e5010_main_0_m_vbusm_r_isc_region_1_end_address_l
0xC01C ISC_REGS_Isam67_c7xv_wrap_main_1_c7xv_soc_isc_region_0_end_address_h — The ISC Region 0 End Address High Register defines the end address bits 47 to 32 for the initiator Isam67_c7xv_wrap_main_1.c7xv_soc region 0 ISC.
  [15:0] END_ADDRESS_H — End address bits 47 to 32.
0xC020 ISC_REGS_Isam67_c7xv_wrap_main_1_c7xv_soc_isc_region_1_control access not given reset 0x102100 — The ISC Region 1 Control Register defines the control fields for the initiator Isam67_c7xv_wrap_main_1.c7xv_soc region 1 ISC.
  fields as ISC_REGS_Ik3_vpu_wave521cl_main_0_pri_m_vbusm_r_async_isc_region_0_control
0xC030 ISC_REGS_Isam67_c7xv_wrap_main_1_c7xv_soc_isc_region_1_start_address_l — The ISC Region 1 Start Address Low Register defines the start address bits 31 to 0 for the initiator Isam67_c7xv_wrap_main_1.c7xv_soc region 1 ISC.
  fields as ISC_REGS_Ik3_jpgenc_e5010_main_0_m_vbusm_r_isc_region_1_start_address_l
0xC034 ISC_REGS_Isam67_c7xv_wrap_main_1_c7xv_soc_isc_region_1_start_address_h — The ISC Region 1 Start Address High Register defines the start address bits 47 to 32 for the initiator Isam67_c7xv_wrap_main_1.c7xv_soc region 1 ISC.
  [15:0] START_ADDRESS_H — Start address bits 47 to 32.
0xC038 ISC_REGS_Isam67_c7xv_wrap_main_1_c7xv_soc_isc_region_1_end_address_l access per field reset 0xFFF — The ISC Region 1 End Address Low Register defines the end included address bits 31 to 0 for the initiator Isam67_c7xv_wrap_main_1.c7xv_soc region 1 ISC.
  fields as ISC_REGS_Ik3_jpgenc_e5010_main_0_m_vbusm_r_isc_region_1_end_address_l
0xC03C ISC_REGS_Isam67_c7xv_wrap_main_1_c7xv_soc_isc_region_1_end_address_h — The ISC Region 1 End Address High Register defines the end address bits 47 to 32 for the initiator Isam67_c7xv_wrap_main_1.c7xv_soc region 1 ISC.
  [15:0] END_ADDRESS_H — End address bits 47 to 32.
0xC040 ISC_REGS_Isam67_c7xv_wrap_main_1_c7xv_soc_isc_region_def_control access not given reset 0x10214A — The ISC Default Region Control Register defines the control fields for the initiator Isam67_c7xv_wrap_main_1.c7xv_soc region 2 ISC.
  fields as ISC_REGS_Ik3_jpgenc_e5010_main_0_m_vbusm_r_isc_region_def_control
{0xC400+0x20*i} ISC_REGS_Isam67_dmpac_wrap_main_0_data_mst_isc_region_{i}_control access not given reset 0x106900 (i=0..31) — The ISC Region {i} Control Register defines the control fields for the initiator Isam67_dmpac_wrap_main_0.data_mst region {i} ISC.
  fields as ISC_REGS_Ik3_vpu_wave521cl_main_0_pri_m_vbusm_r_async_isc_region_0_control
{0xC410+0x20*i} ISC_REGS_Isam67_dmpac_wrap_main_0_data_mst_isc_region_{i}_start_address_l (i=0..31) — The ISC Region {i} Start Address Low Register defines the start address bits 31 to 0 for the initiator Isam67_dmpac_wrap_main_0.data_mst region {i} ISC.
  fields as ISC_REGS_Ik3_jpgenc_e5010_main_0_m_vbusm_r_isc_region_1_start_address_l
{0xC414+0x20*i} ISC_REGS_Isam67_dmpac_wrap_main_0_data_mst_isc_region_{i}_start_address_h (i=0..31) — The ISC Region {i} Start Address High Register defines the start address bits 47 to 32 for the initiator Isam67_dmpac_wrap_main_0.data_mst region {i} ISC.
  [15:0] START_ADDRESS_H — Start address bits 47 to 32.
{0xC418+0x20*i} ISC_REGS_Isam67_dmpac_wrap_main_0_data_mst_isc_region_{i}_end_address_l access per field reset 0xFFF (i=0..31) — The ISC Region {i} End Address Low Register defines the end included address bits 31 to 0 for the initiator Isam67_dmpac_wrap_main_0.data_mst region {i} ISC.
  fields as ISC_REGS_Ik3_jpgenc_e5010_main_0_m_vbusm_r_isc_region_1_end_address_l
{0xC41C+0x20*i} ISC_REGS_Isam67_dmpac_wrap_main_0_data_mst_isc_region_{i}_end_address_h (i=0..31) — The ISC Region {i} End Address High Register defines the end address bits 47 to 32 for the initiator Isam67_dmpac_wrap_main_0.data_mst region {i} ISC.
  [15:0] END_ADDRESS_H — End address bits 47 to 32.
0xC800 ISC_REGS_Isam67_dmpac_wrap_main_0_data_mst_isc_region_def_control access not given reset 0x10694A — The ISC Default Region Control Register defines the control fields for the initiator Isam67_dmpac_wrap_main_0.data_mst region 32 ISC.
  fields as ISC_REGS_Ik3_jpgenc_e5010_main_0_m_vbusm_r_isc_region_def_control
